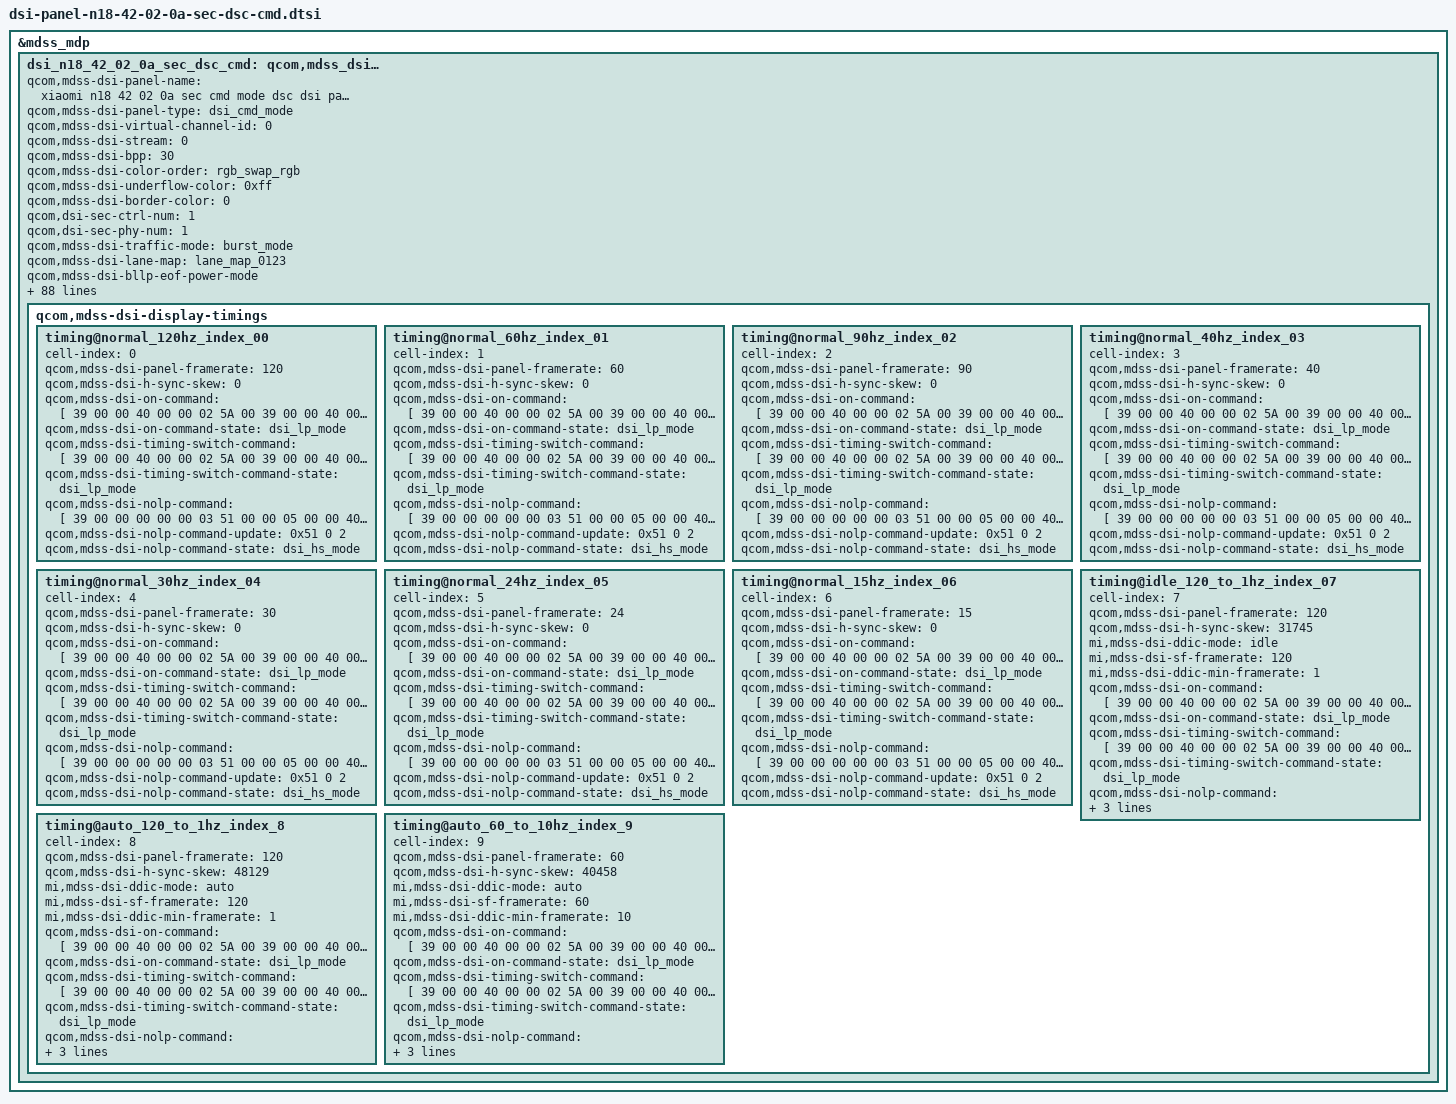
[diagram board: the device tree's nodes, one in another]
&mdss_mdp {
	dsi_n18_42_02_0a_sec_dsc_cmd: qcom,mdss_dsi_n18_42_02_0a_sec_dsc_cmd {
		qcom,mdss-dsi-panel-name = "xiaomi n18 42 02 0a sec cmd mode dsc dsi panel";
		qcom,mdss-dsi-panel-type = "dsi_cmd_mode";
		qcom,mdss-dsi-virtual-channel-id = <0>;
		qcom,mdss-dsi-stream = <0>;
		qcom,mdss-dsi-bpp = <30>;
		qcom,mdss-dsi-color-order = "rgb_swap_rgb";
		qcom,mdss-dsi-underflow-color = <0xff>;
		qcom,mdss-dsi-border-color = <0>;
		qcom,dsi-sec-ctrl-num = <1>;
		qcom,dsi-sec-phy-num = <1>;

		qcom,mdss-dsi-traffic-mode = "burst_mode";
		qcom,mdss-dsi-lane-map = "lane_map_0123";
		qcom,mdss-dsi-bllp-eof-power-mode;
		qcom,mdss-dsi-bllp-power-mode;
		qcom,mdss-dsi-lane-0-state;
		qcom,mdss-dsi-lane-1-state;
		qcom,mdss-dsi-lane-2-state;
		qcom,mdss-dsi-lane-3-state;
		qcom,mdss-dsi-dma-trigger = "trigger_sw";
		qcom,mdss-dsi-mdp-trigger = "none";
		qcom,mdss-dsi-reset-sequence = <0 1>, <1 10>;
		qcom,mdss-pan-physical-width-dimension = <656>;
		qcom,mdss-pan-physical-height-dimension = <1533>;
		qcom,mdss-dsi-te-pin-select = <1>;
		qcom,mdss-dsi-wr-mem-start = <0x2c>;
		qcom,mdss-dsi-wr-mem-continue = <0x3c>;
		qcom,mdss-dsi-te-dcs-command = <1>;
		qcom,mdss-dsi-te-check-enable;
		qcom,mdss-dsi-te-using-te-pin;
		qcom,mdss-dsi-tx-eot-append;
		qcom,mdss-dsi-lp11-init;

		qcom,mdss-dsi-bl-inverted-dbv;
		qcom,bl-update-flag = "delay_until_first_frame";

		qcom,mdss-dsi-panel-hdr-enabled;
		qcom,mdss-dsi-panel-hdr-color-primaries = <14500 15500 32000
			17000 15500 30000 8000 3000>;
		qcom,mdss-dsi-panel-peak-brightness = <17000000>;
		qcom,mdss-dsi-panel-blackness-level = <3230>;

		qcom,mdss-dsi-dma-schedule-line = <1>;
		qcom,mdss-dsi-dma-schedule-window = <50>;

		/* IRQF_ONESHOT | IRQF_TRIGGER_HIGH */
		mi,esd-err-irq-gpio = <&tlmm 137 0x2004>;
		//qcom,spr-pack-type = "pentile";

		mi,panel-id = <0x004E3138 0x5342020A>;

		mi,ddic-round-corner-enabled;

		mi,flat-need-sync-te;
		mi,flatmode-default-on-enabled;

		mi,flatmode-status-check-enabled;
		mi,mdss-dsi-panel-flatmode-status-command = [
			06 01 00 01 00 00 01 5F
		];
		mi,mdss-dsi-panel-flatmode-status-command-state = "dsi_hs_mode";
		mi,mdss-dsi-panel-flatmode-status-read-length = <1>;
		mi,mdss-dsi-panel-flatmode-on-status-value = <0x00>;

		mi,mdss-dsi-panel-wp-read-command = [06 01 00 01 00 00 01 A3];
		mi,mdss-dsi-panel-wp-read-command-state = "dsi_hs_mode";
		mi,mdss-dsi-panel-wp-read-length = <8>;

		mi,mdss-dsi-panel-cell-id-read-command = [06 01 00 01 00 00 01 B1];
		mi,mdss-dsi-panel-cell-id-read-pre-tx-command = [
			39 00 00 40 00 00 06 F0 55 AA 52 08 00
			15 00 00 00 00 00 02 EA 10
		];
		mi,mdss-dsi-panel-cell-id-read-after-tx-command = [
			39 00 00 40 00 00 06 F0 55 AA 52 08 00
			15 00 00 00 00 00 02 EA 00
		];
		mi,mdss-dsi-panel-cell-id-read-pre-tx-command-state = "dsi_hs_mode";
		mi,mdss-dsi-panel-cell-id-read-after-tx-command-state = "dsi_hs_mode";
		mi,mdss-dsi-panel-cell-id-read-command-state = "dsi_hs_mode";
		mi,mdss-dsi-panel-cell-id-read-length = <13>;
		/* esd-check reg_read */
		//qcom,esd-check-enabled;
		//qcom,esd-aod-check-enabled;
		//mi,mdss-dsi-panel-status-check-interval = <1000>;
		//qcom,mdss-dsi-panel-status-check-mode = "reg_read";
		//mi,mdss-dsi-panel-status-offset-command = [39 00 00 00 00 00 03 FF 5A 82
		//						  39 00 00 00 00 00 02 65 01];
		//qcom,mdss-dsi-panel-status-command = [06 01 00 00 00 00 01 F9];
		//mi,mdss-dsi-panel-status-after-command = [39 00 00 00 00 00 03 FF 5A 00];
		//qcom,mdss-dsi-panel-status-command-state = "dsi_lp_mode";
		//mi,mdss-dsi-panel-status-offset-command-state = "dsi_lp_mode";
		//mi,mdss-dsi-panel-status-after-command-state = "dsi_lp_mode";
		//qcom,mdss-dsi-panel-status-value = <0x08>;
		//qcom,mdss-dsi-panel-status-read-length = <1>;

		mi,panel-on-dimming-delay = <120>;
		mi,max-brightness-clone = <16383>;

		mi,mdss-dsi-fac-bl-max-level = <11467>;
		mi,mdss-fac-brightness-max-level = <11467>;
		mi,doze-hbm-dbv-level = <984>;
		mi,doze-lbm-dbv-level = <65>;

		qcom,mdss-dsi-display-timings {
			timing@normal_120hz_index_00 {
				#include "dsi-panel-n18-42-02-0a-sec-dsc-cmd-common.dtsi"
				cell-index = <0>;
				qcom,mdss-dsi-panel-framerate = <120>;
				qcom,mdss-dsi-h-sync-skew = <0>;
				qcom,mdss-dsi-on-command = [
					#include "dsi-panel-n18-42-02-0a-sec-dsc-cmd-dsi-on-common.dtsi"
					/*FIX TE ON*/
					39 00 00 40 00 00 02 5A 00
					/* Frame=120hz */
					39 00 00 40 00 00 02 6D 00
					39 00 00 40 00 00 02 6F 04
					// 0x35,0x00=120hz; 0x35,0x01=120/2=60hz; 0x35,0x02=120/3=40hz;
					39 00 00 40 00 00 02 35 00
					39 00 00 40 00 00 06 F0 55 AA 52 08 00
					39 00 00 40 00 00 02 6F D9
					39 00 00 40 00 00 02 BA 04
					39 00 00 40 00 00 06 F0 55 AA 52 08 00
					39 00 00 40 00 00 02 6F 08
					39 00 00 40 00 00 02 B2 80
					39 00 00 40 00 00 03 51 00 00
					39 00 00 40 00 00 02 53 20
					39 00 00 40 00 00 02 26 00
					/*video trim*/
					39 00 00 40 00 00 06 F0 55 AA 52 08 01
					39 00 00 00 00 00 2A C3 DD 06 20 0F FF 00 06 20 0F FF 00 06 26 1B 05 4E 15 06 26 1B 05 4E 15 06 26 1B 05 4E 15 06 26 1B 05 4E 15 06 26 1B 05 4E 15
					05 00 00 00 78 00 01 11
					05 00 00 00 00 00 01 29
				];
				qcom,mdss-dsi-on-command-state = "dsi_lp_mode";

				qcom,mdss-dsi-timing-switch-command = [
					/*FIX TE ON*/
					39 00 00 40 00 00 02 5A 00
					/* Frame=120hz */
					39 00 00 40 00 00 02 6D 00
					39 00 00 40 00 00 02 6F 04
					// 0x35,0x00=120hz; 0x35,0x01=120/2=60hz; 0x35,0x02=120/3=40hz;
					39 00 00 40 00 00 02 35 00
					39 00 00 40 00 00 06 F0 55 AA 52 08 00
					39 00 00 40 00 00 02 6F D9
					39 00 00 40 00 00 02 BA 04
					39 00 00 40 00 00 06 F0 55 AA 52 08 00
					39 00 00 40 00 00 02 6F 08
					39 00 00 00 00 00 02 B2 80
				];
				qcom,mdss-dsi-timing-switch-command-state = "dsi_lp_mode";

				qcom,mdss-dsi-nolp-command = [
					39 00 00 00 00 00 03 51 00 00
					/* AOD OFF */
					05 00 00 40 00 00 01 38
					39 00 00 40 00 00 02 5A 00
					39 00 00 40 00 00 02 6F 04
					39 00 00 00 00 00 02 35 00
				];
				qcom,mdss-dsi-nolp-command-update = <0x51 0 2>;
				qcom,mdss-dsi-nolp-command-state = "dsi_hs_mode";

			};

			timing@normal_60hz_index_01 {
				#include "dsi-panel-n18-42-02-0a-sec-dsc-cmd-common.dtsi"
				cell-index = <1>;
				qcom,mdss-dsi-panel-framerate = <60>;
				qcom,mdss-dsi-h-sync-skew = <0>;

				qcom,mdss-dsi-on-command = [
					#include "dsi-panel-n18-42-02-0a-sec-dsc-cmd-dsi-on-common.dtsi"
					/*FIX TE ON*/
					39 00 00 40 00 00 02 5A 00
					/* Frame=60hz */
					39 00 00 40 00 00 02 6D 01
					39 00 00 40 00 00 02 6F 04
					// 0x35,0x00=120hz; 0x35,0x01=120/2=60hz; 0x35,0x02=120/3=40hz;
					39 00 00 40 00 00 02 35 01
					39 00 00 40 00 00 06 F0 55 AA 52 08 00
					39 00 00 40 00 00 02 6F D9
					39 00 00 40 00 00 02 BA 04
					39 00 00 40 00 00 06 F0 55 AA 52 08 00
					39 00 00 40 00 00 02 6F 08
					39 00 00 40 00 00 02 B2 80
					39 00 00 40 00 00 03 51 00 00
					39 00 00 40 00 00 02 53 20
					39 00 00 40 00 00 02 26 00
					/*video trim*/
					39 00 00 40 00 00 06 F0 55 AA 52 08 01
					39 00 00 00 00 00 2A C3 DD 06 20 0F FF 00 06 20 0F FF 00 06 26 1B 05 4E 15 06 26 1B 05 4E 15 06 26 1B 05 4E 15 06 26 1B 05 4E 15 06 26 1B 05 4E 15
					05 00 00 00 78 00 01 11
					05 00 00 00 00 00 01 29
				];
				qcom,mdss-dsi-on-command-state = "dsi_lp_mode";

				qcom,mdss-dsi-timing-switch-command = [
					/*FIX TE ON*/
					39 00 00 40 00 00 02 5A 00
					/* Frame=60hz */
					39 00 00 40 00 00 02 6D 01
					39 00 00 40 00 00 02 6F 04
					// 0x35,0x00=120hz; 0x35,0x01=120/2=60hz; 0x35,0x02=120/3=40hz;
					39 00 00 40 00 00 02 35 01
					39 00 00 40 00 00 06 F0 55 AA 52 08 00
					39 00 00 40 00 00 02 6F D9
					39 00 00 40 00 00 02 BA 04
					39 00 00 40 00 00 06 F0 55 AA 52 08 00
					39 00 00 40 00 00 02 6F 08
					39 00 00 00 00 00 02 B2 80
				];
				qcom,mdss-dsi-timing-switch-command-state = "dsi_lp_mode";

				qcom,mdss-dsi-nolp-command = [
					39 00 00 00 00 00 03 51 00 00
					/* AOD OFF */
					05 00 00 40 00 00 01 38
					39 00 00 40 00 00 02 5A 00
					39 00 00 40 00 00 02 6F 04
					39 00 00 00 00 00 02 35 01
				];
				qcom,mdss-dsi-nolp-command-update = <0x51 0 2>;
				qcom,mdss-dsi-nolp-command-state = "dsi_hs_mode";
			};

			timing@normal_90hz_index_02 {
				#include "dsi-panel-n18-42-02-0a-sec-dsc-cmd-common.dtsi"
				cell-index = <2>;
				qcom,mdss-dsi-panel-framerate = <90>;
				qcom,mdss-dsi-h-sync-skew = <0>;

				qcom,mdss-dsi-on-command = [
					#include "dsi-panel-n18-42-02-0a-sec-dsc-cmd-dsi-on-common.dtsi"
					/*FIX TE ON*/
					39 00 00 40 00 00 02 5A 00
					/* Frame=90hz */
					39 00 00 40 00 00 02 6F 04
					39 00 00 40 00 00 02 35 00
					39 00 00 40 00 00 02 6D 0B
					39 00 00 40 00 00 03 51 00 00
					39 00 00 40 00 00 02 53 20
					39 00 00 40 00 00 02 26 00
					/*video trim*/
					39 00 00 40 00 00 06 F0 55 AA 52 08 01
					39 00 00 00 00 00 2A C3 DD 06 20 0F FF 00 06 20 0F FF 00 06 26 1B 05 4E 15 06 26 1B 05 4E 15 06 26 1B 05 4E 15 06 26 1B 05 4E 15 06 26 1B 05 4E 15
					05 00 00 00 78 00 01 11
					05 00 00 00 00 00 01 29
				];
				qcom,mdss-dsi-on-command-state = "dsi_lp_mode";

				qcom,mdss-dsi-timing-switch-command = [
					/*FIX TE ON*/
					39 00 00 40 00 00 02 5A 00
					/* Frame=90hz */
					39 00 00 40 00 00 02 6F 04
					39 00 00 40 00 00 02 35 00
					39 00 00 00 00 00 02 6D 0B
				];
				qcom,mdss-dsi-timing-switch-command-state = "dsi_lp_mode";

				qcom,mdss-dsi-nolp-command = [
					39 00 00 00 00 00 03 51 00 00
					/* AOD OFF */
					05 00 00 40 00 00 01 38
					39 00 00 40 00 00 02 5A 00
					39 00 00 40 00 00 02 6F 04
					39 00 00 00 00 00 02 35 00
				];
				qcom,mdss-dsi-nolp-command-update = <0x51 0 2>;
				qcom,mdss-dsi-nolp-command-state = "dsi_hs_mode";
			};

			timing@normal_40hz_index_03 {
				#include "dsi-panel-n18-42-02-0a-sec-dsc-cmd-common.dtsi"
				cell-index = <3>;
				qcom,mdss-dsi-panel-framerate = <40>;
				qcom,mdss-dsi-h-sync-skew = <0>;

				qcom,mdss-dsi-on-command = [
					#include "dsi-panel-n18-42-02-0a-sec-dsc-cmd-dsi-on-common.dtsi"
					/*FIX TE ON*/
					39 00 00 40 00 00 02 5A 00
					/* Frame=40hz */
					39 00 00 40 00 00 02 6D 02
					39 00 00 40 00 00 02 6F 04
					// 0x35,0x00=120hz; 0x35,0x01=120/2=60hz; 0x35,0x02=120/3=40hz;
					39 00 00 40 00 00 02 35 02
					39 00 00 40 00 00 06 F0 55 AA 52 08 00
					39 00 00 40 00 00 02 6F D9
					39 00 00 40 00 00 02 BA 04
					39 00 00 40 00 00 06 F0 55 AA 52 08 00
					39 00 00 40 00 00 02 6F 08
					39 00 00 40 00 00 02 B2 80
					39 00 00 40 00 00 03 51 00 00
					39 00 00 40 00 00 02 53 20
					39 00 00 40 00 00 02 26 00
					/*video trim*/
					39 00 00 40 00 00 06 F0 55 AA 52 08 01
					39 00 00 00 00 00 2A C3 DD 06 20 0F FF 00 06 20 0F FF 00 06 26 1B 05 4E 15 06 26 1B 05 4E 15 06 26 1B 05 4E 15 06 26 1B 05 4E 15 06 26 1B 05 4E 15
					05 00 00 00 78 00 01 11
					05 00 00 00 00 00 01 29
				];
				qcom,mdss-dsi-on-command-state = "dsi_lp_mode";

				qcom,mdss-dsi-timing-switch-command = [
					/*FIX TE ON*/
					39 00 00 40 00 00 02 5A 00
					/* Frame=40hz */
					39 00 00 40 00 00 02 6D 02
					39 00 00 40 00 00 02 6F 04
					// 0x35,0x00=120hz; 0x35,0x01=120/2=60hz; 0x35,0x02=120/3=40hz;
					39 00 00 40 00 00 02 35 02
					39 00 00 40 00 00 06 F0 55 AA 52 08 00
					39 00 00 40 00 00 02 6F D9
					39 00 00 40 00 00 02 BA 04
					39 00 00 40 00 00 06 F0 55 AA 52 08 00
					39 00 00 40 00 00 02 6F 08
					39 00 00 00 00 00 02 B2 80
				];
				qcom,mdss-dsi-timing-switch-command-state = "dsi_lp_mode";

				qcom,mdss-dsi-nolp-command = [
					39 00 00 00 00 00 03 51 00 00
					/* AOD OFF */
					05 00 00 40 00 00 01 38
					39 00 00 40 00 00 02 5A 00
					39 00 00 40 00 00 02 6F 04
					39 00 00 00 00 00 02 35 02
				];
				qcom,mdss-dsi-nolp-command-update = <0x51 0 2>;
				qcom,mdss-dsi-nolp-command-state = "dsi_hs_mode";
			};

			timing@normal_30hz_index_04 {
				#include "dsi-panel-n18-42-02-0a-sec-dsc-cmd-common.dtsi"
				cell-index = <4>;
				qcom,mdss-dsi-panel-framerate = <30>;
				qcom,mdss-dsi-h-sync-skew = <0>;

				qcom,mdss-dsi-on-command = [
					#include "dsi-panel-n18-42-02-0a-sec-dsc-cmd-dsi-on-common.dtsi"
					/*FIX TE ON*/
					39 00 00 40 00 00 02 5A 00
					/* Frame=30hz */
					39 00 00 40 00 00 02 6D 03
					39 00 00 40 00 00 02 6F 04
					// 0x35,0x00=120hz; 0x35,0x01=120/2=60hz; 0x35,0x02=120/3=40hz;
					39 00 00 40 00 00 02 35 03
					39 00 00 40 00 00 06 F0 55 AA 52 08 00
					39 00 00 40 00 00 02 6F D9
					39 00 00 40 00 00 02 BA 04
					39 00 00 40 00 00 06 F0 55 AA 52 08 00
					39 00 00 40 00 00 02 6F 08
					39 00 00 40 00 00 02 B2 80
					39 00 00 40 00 00 03 51 00 00
					39 00 00 40 00 00 02 53 20
					39 00 00 40 00 00 02 26 00
					/*video trim*/
					39 00 00 40 00 00 06 F0 55 AA 52 08 01
					39 00 00 00 00 00 2A C3 DD 06 20 0F FF 00 06 20 0F FF 00 06 26 1B 05 4E 15 06 26 1B 05 4E 15 06 26 1B 05 4E 15 06 26 1B 05 4E 15 06 26 1B 05 4E 15
					05 00 00 00 78 00 01 11
					05 00 00 00 00 00 01 29
				];
				qcom,mdss-dsi-on-command-state = "dsi_lp_mode";

				qcom,mdss-dsi-timing-switch-command = [
					/*FIX TE ON*/
					39 00 00 40 00 00 02 5A 00
					/* Frame=30hz */
					39 00 00 40 00 00 02 6D 03
					39 00 00 40 00 00 02 6F 04
					// 0x35,0x00=120hz; 0x35,0x01=120/2=60hz; 0x35,0x02=120/3=40hz;
					39 00 00 40 00 00 02 35 03
					39 00 00 40 00 00 06 F0 55 AA 52 08 00
					39 00 00 40 00 00 02 6F D9
					39 00 00 40 00 00 02 BA 04
					39 00 00 40 00 00 06 F0 55 AA 52 08 00
					39 00 00 40 00 00 02 6F 08
					39 00 00 00 00 00 02 B2 80
				];
				qcom,mdss-dsi-timing-switch-command-state = "dsi_lp_mode";

				qcom,mdss-dsi-nolp-command = [
					39 00 00 00 00 00 03 51 00 00
					/* AOD OFF */
					05 00 00 40 00 00 01 38
					39 00 00 40 00 00 02 5A 00
					39 00 00 40 00 00 02 6F 04
					39 00 00 00 00 00 02 35 03
				];
				qcom,mdss-dsi-nolp-command-update = <0x51 0 2>;
				qcom,mdss-dsi-nolp-command-state = "dsi_hs_mode";
			};

			timing@normal_24hz_index_05 {
				#include "dsi-panel-n18-42-02-0a-sec-dsc-cmd-common.dtsi"
				cell-index = <5>;
				qcom,mdss-dsi-panel-framerate = <24>;
				qcom,mdss-dsi-h-sync-skew = <0>;

				qcom,mdss-dsi-on-command = [
					#include "dsi-panel-n18-42-02-0a-sec-dsc-cmd-dsi-on-common.dtsi"
					/*FIX TE ON*/
					39 00 00 40 00 00 02 5A 00
					/* Frame=24hz */
					39 00 00 40 00 00 02 6D 04
					39 00 00 40 00 00 02 6F 04
					// 0x35,0x00=120hz; 0x35,0x01=120/2=60hz; 0x35,0x02=120/3=40hz;
					39 00 00 40 00 00 02 35 04
					39 00 00 40 00 00 06 F0 55 AA 52 08 00
					39 00 00 40 00 00 02 6F D9
					39 00 00 40 00 00 02 BA 04
					39 00 00 40 00 00 06 F0 55 AA 52 08 00
					39 00 00 40 00 00 02 6F 08
					39 00 00 40 00 00 02 B2 80
					39 00 00 40 00 00 03 51 00 00
					39 00 00 40 00 00 02 53 20
					39 00 00 40 00 00 02 26 00
					/*video trim*/
					39 00 00 40 00 00 06 F0 55 AA 52 08 01
					39 00 00 00 00 00 2A C3 DD 06 20 0F FF 00 06 20 0F FF 00 06 26 1B 05 4E 15 06 26 1B 05 4E 15 06 26 1B 05 4E 15 06 26 1B 05 4E 15 06 26 1B 05 4E 15
					05 00 00 00 78 00 01 11
					05 00 00 00 00 00 01 29
				];
				qcom,mdss-dsi-on-command-state = "dsi_lp_mode";

				qcom,mdss-dsi-timing-switch-command = [
					/*FIX TE ON*/
					39 00 00 40 00 00 02 5A 00
					/* Frame=24hz */
					39 00 00 40 00 00 02 6D 04
					39 00 00 40 00 00 02 6F 04
					// 0x35,0x00=120hz; 0x35,0x01=120/2=60hz; 0x35,0x02=120/3=40hz;
					39 00 00 40 00 00 02 35 04
					39 00 00 40 00 00 06 F0 55 AA 52 08 00
					39 00 00 40 00 00 02 6F D9
					39 00 00 40 00 00 02 BA 04
					39 00 00 40 00 00 06 F0 55 AA 52 08 00
					39 00 00 40 00 00 02 6F 08
					39 00 00 00 00 00 02 B2 80
				];
				qcom,mdss-dsi-timing-switch-command-state = "dsi_lp_mode";

				qcom,mdss-dsi-nolp-command = [
					39 00 00 00 00 00 03 51 00 00
					/* AOD OFF */
					05 00 00 40 00 00 01 38
					39 00 00 40 00 00 02 5A 00
					39 00 00 40 00 00 02 6F 04
					39 00 00 00 00 00 02 35 04
				];
				qcom,mdss-dsi-nolp-command-update = <0x51 0 2>;
				qcom,mdss-dsi-nolp-command-state = "dsi_hs_mode";
			};

			timing@normal_15hz_index_06 {
				#include "dsi-panel-n18-42-02-0a-sec-dsc-cmd-common.dtsi"
				cell-index = <6>;
				qcom,mdss-dsi-panel-framerate = <15>;
				qcom,mdss-dsi-h-sync-skew = <0>;

				qcom,mdss-dsi-on-command = [
					#include "dsi-panel-n18-42-02-0a-sec-dsc-cmd-dsi-on-common.dtsi"
					/*FIX TE ON*/
					39 00 00 40 00 00 02 5A 00
					/* Frame=15hz */
					39 00 00 40 00 00 02 6D 06
					39 00 00 40 00 00 02 6F 04
					// 0x35,0x00=120hz; 0x35,0x01=120/2=60hz; 0x35,0x02=120/3=40hz;
					39 00 00 40 00 00 02 35 07
					39 00 00 40 00 00 06 F0 55 AA 52 08 00
					39 00 00 40 00 00 02 6F D9
					39 00 00 40 00 00 02 BA 04
					39 00 00 40 00 00 06 F0 55 AA 52 08 00
					39 00 00 40 00 00 02 6F 08
					39 00 00 40 00 00 02 B2 80
					39 00 00 40 00 00 03 51 00 00
					39 00 00 40 00 00 02 53 20
					39 00 00 40 00 00 02 26 00
					/*video trim*/
					39 00 00 40 00 00 06 F0 55 AA 52 08 01
					39 00 00 00 00 00 2A C3 DD 06 20 0F FF 00 06 20 0F FF 00 06 26 1B 05 4E 15 06 26 1B 05 4E 15 06 26 1B 05 4E 15 06 26 1B 05 4E 15 06 26 1B 05 4E 15
					05 00 00 00 78 00 01 11
					05 00 00 00 00 00 01 29
				];
				qcom,mdss-dsi-on-command-state = "dsi_lp_mode";

				qcom,mdss-dsi-timing-switch-command = [
					/*FIX TE ON*/
					39 00 00 40 00 00 02 5A 00
					/* Frame=15hz */
					39 00 00 40 00 00 02 6D 06
					39 00 00 40 00 00 02 6F 04
					// 0x35,0x00=120hz; 0x35,0x01=120/2=60hz; 0x35,0x02=120/3=40hz;
					39 00 00 40 00 00 02 35 07
					39 00 00 40 00 00 06 F0 55 AA 52 08 00
					39 00 00 40 00 00 02 6F D9
					39 00 00 40 00 00 02 BA 04
					39 00 00 40 00 00 06 F0 55 AA 52 08 00
					39 00 00 40 00 00 02 6F 08
					39 00 00 00 00 00 02 B2 80
				];
				qcom,mdss-dsi-timing-switch-command-state = "dsi_lp_mode";

				qcom,mdss-dsi-nolp-command = [
					39 00 00 00 00 00 03 51 00 00
					/* AOD OFF */
					05 00 00 40 00 00 01 38
					39 00 00 40 00 00 02 5A 00
					39 00 00 40 00 00 02 6F 04
					39 00 00 00 00 00 02 35 07
				];
				qcom,mdss-dsi-nolp-command-update = <0x51 0 2>;
				qcom,mdss-dsi-nolp-command-state = "dsi_hs_mode";
			};
			timing@idle_120_to_1hz_index_07 {
				#include "dsi-panel-n18-42-02-0a-sec-dsc-cmd-common.dtsi"
				cell-index = <7>;
				qcom,mdss-dsi-panel-framerate = <120>;
				/* ---------------------------- */
				/* | 15 - 14 | 13 - 7 | 6 - 0 | */
				/* ---------------------------- */
				/* |   mode  | sf fps | min fps| */
				/* ---------------------------- -*/
				/* mode: 1 idle, 2 auto, 3 qsync */
				/*   1 << 14 | 120 << 7 | 1     */
				qcom,mdss-dsi-h-sync-skew = <31745>;
				/* mode: 0 normal, 1 idle, 2 auto, 3 qsync, 4 diff, 5 test */
				mi,mdss-dsi-ddic-mode = "idle";
				mi,mdss-dsi-sf-framerate = <120>;
				mi,mdss-dsi-ddic-min-framerate = <1>;

				qcom,mdss-dsi-on-command = [
					#include "dsi-panel-n18-42-02-0a-sec-dsc-cmd-dsi-on-common.dtsi"
					/*FIX TE ON*/
					39 00 00 40 00 00 02 5A 00
					/* Frame=1hz */
					39 00 00 40 00 00 02 6D 09
					39 00 00 40 00 00 02 6F 04
					// 0x35,0x00=120hz; 0x35,0x01=120/2=60hz; 0x35,0x02=120/3=40hz;
					39 00 00 40 00 00 02 35 00
					39 00 00 40 00 00 06 F0 55 AA 52 08 00
					39 00 00 40 00 00 02 6F D9
					39 00 00 40 00 00 02 BA 00
					39 00 00 40 00 00 06 F0 55 AA 52 08 00
					39 00 00 40 00 00 02 6F 08
					39 00 00 40 00 00 02 B2 C0
					39 00 00 40 00 00 03 51 00 00
					39 00 00 40 00 00 02 53 20
					39 00 00 40 00 00 02 26 00
					/*video trim*/
					39 00 00 40 00 00 06 F0 55 AA 52 08 01
					39 00 00 00 00 00 2A C3 DD 06 20 0F FF 00 06 20 0F FF 00 06 26 1B 05 4E 15 06 26 1B 05 4E 15 06 26 1B 05 4E 15 06 26 1B 05 4E 15 06 26 1B 05 4E 15
					05 00 00 00 78 00 01 11
					05 00 00 00 00 00 01 29
				];
				qcom,mdss-dsi-on-command-state = "dsi_lp_mode";

				qcom,mdss-dsi-timing-switch-command = [
					/*FIX TE ON*/
					39 00 00 40 00 00 02 5A 00
					/* Frame=1hz */
					39 00 00 40 00 00 02 6D 09
					39 00 00 40 00 00 02 6F 04
					// 0x35,0x00=120hz; 0x35,0x01=120/2=60hz; 0x35,0x02=120/3=40hz;
					39 00 00 40 00 00 02 35 00
					39 00 00 40 00 00 06 F0 55 AA 52 08 00
					39 00 00 40 00 00 02 6F D9
					39 00 00 40 00 00 02 BA 00
					39 00 00 40 00 00 06 F0 55 AA 52 08 00
					39 00 00 40 00 00 02 6F 08
					39 00 00 00 00 00 02 B2 C0
				];
				qcom,mdss-dsi-timing-switch-command-state = "dsi_lp_mode";

				qcom,mdss-dsi-nolp-command = [
					39 00 00 00 00 00 03 51 00 00
					/* AOD OFF */
					05 00 00 40 00 00 01 38
					39 00 00 40 00 00 02 5A 00
					39 00 00 40 00 00 02 6F 04
					39 00 00 00 00 00 02 35 00
				];
				qcom,mdss-dsi-nolp-command-update = <0x51 0 2>;
				qcom,mdss-dsi-nolp-command-state = "dsi_hs_mode";
			};
			timing@auto_120_to_1hz_index_8{
				#include "dsi-panel-n18-42-02-0a-sec-dsc-cmd-common.dtsi"
				cell-index = <8>;
				qcom,mdss-dsi-panel-framerate = <120>;
				/* ---------------------------- */
				/* | 15 - 14 | 13 - 7 | 6 - 0 | */
				/* ---------------------------- */
				/* |   mode  | sf fps | min fps| */
				/* ---------------------------- -*/
				/* mode: 1 idle, 2 auto, 3 qsync */
				/*   2 << 14 | 120 << 7 | 10     */
				qcom,mdss-dsi-h-sync-skew = <48129>;
				/* mode: 0 normal, 1 idle, 2 auto, 3 qsync, 4 diff, 5 test */
				mi,mdss-dsi-ddic-mode = "auto";
				mi,mdss-dsi-sf-framerate = <120>;
				mi,mdss-dsi-ddic-min-framerate = <1>;

				qcom,mdss-dsi-on-command = [
					#include "dsi-panel-n18-42-02-0a-sec-dsc-cmd-dsi-on-common.dtsi"
					/*FIX TE ON*/
					39 00 00 40 00 00 02 5A 00
					/* Frame=1hz */
					39 00 00 40 00 00 02 6D 09
					39 00 00 40 00 00 02 6F 04
					// 0x35,0x00=120hz; 0x35,0x01=120/2=60hz; 0x35,0x02=120/3=40hz;
					39 00 00 40 00 00 02 35 00
					39 00 00 40 00 00 06 F0 55 AA 52 08 00
					39 00 00 40 00 00 02 6F D9
					39 00 00 40 00 00 02 BA 00
					39 00 00 40 00 00 06 F0 55 AA 52 08 00
					39 00 00 40 00 00 02 6F 08
					39 00 00 40 00 00 02 B2 C0
					39 00 00 40 00 00 03 51 00 00
					39 00 00 40 00 00 02 53 20
					39 00 00 40 00 00 02 26 00
					/*video trim*/
					39 00 00 40 00 00 06 F0 55 AA 52 08 01
					39 00 00 00 00 00 2A C3 DD 06 20 0F FF 00 06 20 0F FF 00 06 26 1B 05 4E 15 06 26 1B 05 4E 15 06 26 1B 05 4E 15 06 26 1B 05 4E 15 06 26 1B 05 4E 15
					05 00 00 00 78 00 01 11
					05 00 00 00 00 00 01 29
				];
				qcom,mdss-dsi-on-command-state = "dsi_lp_mode";

				qcom,mdss-dsi-timing-switch-command = [
					/*FIX TE ON*/
					39 00 00 40 00 00 02 5A 00
					/* Frame=1hz */
					39 00 00 40 00 00 02 6D 09
					39 00 00 40 00 00 02 6F 04
					// 0x35,0x00=120hz; 0x35,0x01=120/2=60hz; 0x35,0x02=120/3=40hz;
					39 00 00 40 00 00 02 35 00
					39 00 00 40 00 00 06 F0 55 AA 52 08 00
					39 00 00 40 00 00 02 6F D9
					39 00 00 40 00 00 02 BA 00
					39 00 00 40 00 00 06 F0 55 AA 52 08 00
					39 00 00 40 00 00 02 6F 08
					39 00 00 00 00 00 02 B2 C0
				];
				qcom,mdss-dsi-timing-switch-command-state = "dsi_lp_mode";

				qcom,mdss-dsi-nolp-command = [
					39 00 00 00 00 00 03 51 00 00
					/* AOD OFF */
					05 00 00 40 00 00 01 38
					39 00 00 40 00 00 02 5A 00
					39 00 00 40 00 00 02 6F 04
					39 00 00 00 00 00 02 35 00
				];
				qcom,mdss-dsi-nolp-command-update = <0x51 0 2>;
				qcom,mdss-dsi-nolp-command-state = "dsi_hs_mode";
			};
			timing@auto_60_to_10hz_index_9 {
				#include "dsi-panel-n18-42-02-0a-sec-dsc-cmd-common.dtsi"
				cell-index = <9>;
				qcom,mdss-dsi-panel-framerate = <60>;
				/* ---------------------------- */
				/* | 15 - 14 | 13 - 7 | 6 - 0 | */
				/* ---------------------------- */
				/* |   mode  | sf fps | min fps| */
				/* ---------------------------- -*/
				/* mode: 1 idle, 2 auto, 3 qsync */
				/*   2 << 14 | 60 << 7 | 10     */
				qcom,mdss-dsi-h-sync-skew = <40458>;
				/* mode: 0 normal, 1 idle, 2 auto, 3 qsync, 4 diff, 5 test */
				mi,mdss-dsi-ddic-mode = "auto";
				mi,mdss-dsi-sf-framerate = <60>;
				mi,mdss-dsi-ddic-min-framerate = <10>;

				qcom,mdss-dsi-on-command = [
					#include "dsi-panel-n18-42-02-0a-sec-dsc-cmd-dsi-on-common.dtsi"
					/*FIX TE ON*/
					39 00 00 40 00 00 02 5A 00
					/* Frame=1hz */
					39 00 00 40 00 00 02 6D 0C
					39 00 00 40 00 00 02 6F 04
					// 0x35,0x00=120hz; 0x35,0x01=120/2=60hz; 0x35,0x02=120/3=40hz;
					39 00 00 40 00 00 02 35 01
					39 00 00 40 00 00 06 F0 55 AA 52 08 00
					39 00 00 40 00 00 02 6F D9
					39 00 00 40 00 00 02 BA 00
					39 00 00 40 00 00 06 F0 55 AA 52 08 00
					39 00 00 40 00 00 02 6F 08
					39 00 00 40 00 00 02 B2 C0
					39 00 00 40 00 00 03 51 00 00
					39 00 00 40 00 00 02 53 20
					39 00 00 40 00 00 02 26 00
					/*video trim*/
					39 00 00 40 00 00 06 F0 55 AA 52 08 01
					39 00 00 00 00 00 2A C3 DD 06 20 0F FF 00 06 20 0F FF 00 06 26 1B 05 4E 15 06 26 1B 05 4E 15 06 26 1B 05 4E 15 06 26 1B 05 4E 15 06 26 1B 05 4E 15
					05 00 00 00 78 00 01 11
					05 00 00 00 00 00 01 29
				];
				qcom,mdss-dsi-on-command-state = "dsi_lp_mode";

				qcom,mdss-dsi-timing-switch-command = [
					/*FIX TE ON*/
					39 00 00 40 00 00 02 5A 00
					/* Frame=1hz */
					39 00 00 40 00 00 02 6D 0C
					39 00 00 40 00 00 02 6F 04
					// 0x35,0x00=120hz; 0x35,0x01=120/2=60hz; 0x35,0x02=120/3=40hz;
					39 00 00 40 00 00 02 35 01
					39 00 00 40 00 00 06 F0 55 AA 52 08 00
					39 00 00 40 00 00 02 6F D9
					39 00 00 40 00 00 02 BA 00
					39 00 00 40 00 00 06 F0 55 AA 52 08 00
					39 00 00 40 00 00 02 6F 08
					39 00 00 00 00 00 02 B2 C0
				];
				qcom,mdss-dsi-timing-switch-command-state = "dsi_lp_mode";

				qcom,mdss-dsi-nolp-command = [
					39 00 00 00 00 00 03 51 00 00
					/* AOD OFF */
					05 00 00 40 00 00 01 38
					39 00 00 40 00 00 02 5A 00
					39 00 00 40 00 00 02 6F 04
					39 00 00 00 00 00 02 35 01
				];
				qcom,mdss-dsi-nolp-command-update = <0x51 0 2>;
				qcom,mdss-dsi-nolp-command-state = "dsi_hs_mode";
			};
		};
	};
};

&dsi_n18_42_02_0a_sec_dsc_cmd {
	qcom,panel-sec-supply-entries = <&dsi_panel_pwr_supply_sec_N18>;
	qcom,mdss-dsi-sec-bl-pmic-control-type = "bl_ctrl_dcs";
	qcom,mdss-dsi-bl-min-level = <25>;
	qcom,mdss-dsi-bl-max-level = <16383>;
	qcom,bl-dsc-cmd-state = "dsi_hs_mode";
	qcom,mdss-brightness-max-level = <16383>;
	qcom,mdss-brightness-init-level = <1228>;
	qcom,platform-sec-reset-gpio = <&tlmm 128 0>;

	mi,panel-build-id-read-needed;
	mi,panel-build-id-read-length = <1>;
	mi,mdss-dsi-panel-build-id-read-command = [06 01 00 01 00 00 01 DA];
	mi,mdss-dsi-panel-build-id-read-command-state = "dsi_hs_mode";

	mi,disable-ic-dimming-flag;
	qcom,mdss-dsi-panel-vsync-delay;
	qcom,ulps-enabled;
	qcom,dsi-select-sec-clocks = "pll_byte_clk1", "pll_dsi_clk1";
	qcom,mdss-dsi-clk-strength = <0xFF>;
	qcom,mdss-dsi-deemph-eq-strength = <0x88>;
};
